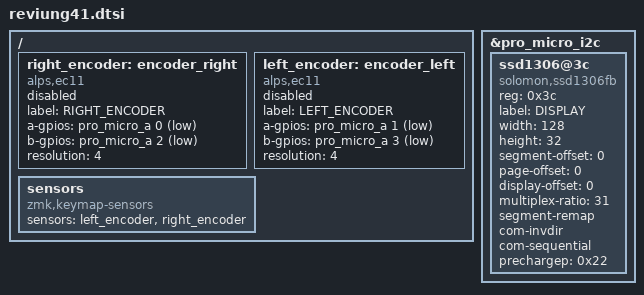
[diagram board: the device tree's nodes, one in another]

/{
        right_encoder: encoder_right {
                compatible = "alps,ec11";
                label = "RIGHT_ENCODER";
                a-gpios = <&pro_micro_a 0 (GPIO_ACTIVE_LOW | GPIO_PULL_UP)>; //F7 in QMK
                b-gpios = <&pro_micro_a 2 (GPIO_ACTIVE_LOW | GPIO_PULL_UP)>; //F5 in QMK
                resolution = <4>;
                status = "disabled";
            };

        left_encoder: encoder_left {
                compatible = "alps,ec11";
                label = "LEFT_ENCODER";
                a-gpios = <&pro_micro_a 1 (GPIO_ACTIVE_LOW | GPIO_PULL_UP)>; //F6 in QMK
                b-gpios = <&pro_micro_a 3 (GPIO_ACTIVE_LOW | GPIO_PULL_UP)>; //F4 in QMK
                resolution = <4>;
                status = "disabled";
            };

        sensors {
                compatible = "zmk,keymap-sensors";
                sensors = <&left_encoder &right_encoder>;
            };
};

//OLED DISPLAY
&pro_micro_i2c {
   status = "okay";

        ssd1306@3c {
                compatible = "solomon,ssd1306fb";
                reg = <0x3c>;
                label = "DISPLAY";
                width = <128>;
                height = <32>;
                segment-offset = <0>;
                page-offset = <0>;
                display-offset = <0>;
                multiplex-ratio = <31>;
                segment-remap;
                com-invdir;
                com-sequential;
                prechargep = <0x22>;
        };
};
